# CY8C4245AXI_483 register map
File version: 0.1
PSoC 4200
Registers are 8-bit, read-write, no defined reset value unless marked. A register's access mark holds for its fields unless they carry their own. Offsets are from the block's base; lines under a group give offsets from that group; [hi:lo] are bit positions; {n}, {i} and the like mark numbered series; 'fields as' and 'values as' point back to an identical list; <NAME> marks a mode.

## Memory map
0x00000000 BuzzerEN
0x00000000 Buzzer

## BuzzerEN
Base 0x00000000
0x400F0073 BuzzerEN_CONTROL_REG

## Buzzer
Base 0x00000000
0x400F0023 Buzzer_COMPARE_Reg_ — UDB.D0 - Assigned Compare Value
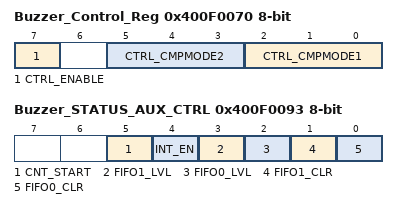
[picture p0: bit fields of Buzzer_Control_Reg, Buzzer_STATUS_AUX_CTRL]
0x400F0070 Buzzer_Control_Reg — UDB Control Register - Assigned Control Register Value
  [7] CTRL_ENABLE — Enable the PWM
  [5:3] CTRL_CMPMODE2 — Compare mode 2
  [2:0] CTRL_CMPMODE1 — Compare mode 1
0x400F0093 Buzzer_STATUS_AUX_CTRL — UDB Auxilliary Control Register
  [5] CNT_START — FIFO0 clear
    0=E_CNT_START0 (Disable counter); 1=E_CNT_START1 (Enable counter)
  [4] INT_EN
    0=E_INT_EN0 (Interrupt disabled); 1=E_INT_EN1 (Interrupt enabled)
  [3] FIFO1_LVL — FIFO level
    0=E_FIFO_LVL_0 (FIFO LVL: input mode: FIFO not full; output mode: FIFO not empty); 1=E_FIFO_LVL_1 (FIFO LVL: input mode: FIFO at least 1/2 empty; output mode: FIFO at least 1/2 full)
  [2] FIFO0_LVL — FIFO level
    values as FIFO1_LVL
  [1] FIFO1_CLR — FIFO1 clear
    0=E_FIFO_CLR_0 (Normal FIFO operation); 1=E_FIFO_CLR_1 (Clear FIFO state)
  [0] FIFO0_CLR — FIFO0 clear
    values as FIFO1_CLR
